# MAX32550 register map
Vendor: Maxim Integrated; File version: 1.0
Registers are 32-bit, read-write, reset 0x0 unless marked. A register's access mark holds for its fields unless they carry their own. Offsets are from the block's base; [hi:lo] are bit positions; {n}, {i} and the like mark numbered series; 'fields as' and 'values as' point back to an identical list.

## SPI0 — Serial Peripheral Interface
Base 0x40018000; register names take the prefix SPI0_
Same registers: SPI1 0x40019000 (register names take the prefix SPI1_), SPI2 0x4001A000 (register names take the prefix SPI2_)
0x00 DATA 16-bit — SPI Data
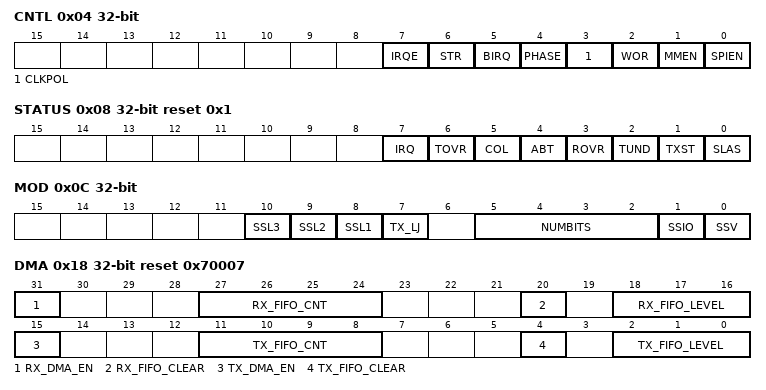
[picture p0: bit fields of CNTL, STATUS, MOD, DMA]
0x04 CNTL — SPI Control Register
  [7] IRQE — Interrupt Request Enable
    0=disable; 1=enable
  [6] STR — Start SPI Interrupt
    0=complete (No operation/complete); 1=Start operation
  [5] BIRQ — Baud Rate Generator Timer Interrupt Request
    0=disable; 1=enable
  [4] PHASE — Phase Select
    0=activeEdge (Transmit on active edge of SCLK); 1=inactiveEdge (Transmit on inactive edge of SCLK)
  [3] CLKPOL — Clock Polarity
    0=idleLo (SCLK idles Low (0) after character transmission/reception.); 1=idleHi (SCLK idles High (1) after character transmission/reception.)
  [2] WOR — Wired OR (open drain) Enable
    0=disable; 1=enable
  [1] MMEN — SPI Master Mode Enable
    0=slave; 1=master
  [0] SPIEN — SPI Enable
    0=disable; 1=enable
0x08 STATUS reset 0x1 — SPI Status Register
  [7] IRQ write-1-clears — SPI Interrupt Request
    0=inactive (No interrupt is pending.); 1=pending (An interrupt is pending.)
  [6] TOVR write-1-clears — Transmit Overrun
    0=noEvent (The event has not occurred); 1=occurred (The event has occurred.)
  [5] COL write-1-clears — Collision
    values as TOVR
  [4] ABT write-1-clears — Slave Mode Transaction Abort
    values as TOVR
  [3] ROVR write-1-clears — Receive Overrun
    values as TOVR
  [2] TUND write-1-clears — Transmit Underrun
    values as TOVR
  [1] TXST ro — Transmit Status
    0=idle; 1=busy
  [0] SLAS ro — Slave Select. If the SPI is in slave mode, this bit indicates if the SPI is selected. If the SPI is in master mode this bit has no meaning.
    0=selected; 1=notSelected
0x0C MOD — SPI Mode Register
  [10] SSL3 — Slave Select 3. If SPI is enabled and in master mode, the SSEL_3 is driven according to this bit.
    0=hi (High); 1=lo (Low)
  [9] SSL2 — Slave Select 2. If SPI is enabled and in master mode, the SSEL_2 is driven according to this bit.
    0=hi (High); 1=lo (Low)
  [8] SSL1 — Slave Select 1. If SPI is enabled and in master mode, the SSEL_1 is driven according to this bit.
    0=hi (High); 1=lo (Low)
  [7] TX_LJ — Transmit Left Justify
    0=disable; 1=enable
  [5:2] NUMBITS
    0=bits16; {v}=bits{v} (v=1..15)
  [1] SSIO — Slave Select I/O
    0=input; 1=output
  [0] SSV — Slave Select Value
    0=lo (The SSEL pin will be driven low.); 1=hi (The SSEL pin will be driven high.)
0x14 BRG 16-bit reset 0xFFFF — Baud Rate Reload Value. The SPI Baud Rate register is a 16-bit reload value for the SPI Baud Rate Generator. The reload value must be greater than or equal to 0002H for proper SPI operation (maximum baud rate is PCLK frequency divided by 4).
0x18 DMA reset 0x70007 — SPI DMA Register
  [31] RX_DMA_EN — Receive DMA Enable
    0=disable; 1=enable
  [27:24] RX_FIFO_CNT ro — Receive FIFO Count
  [20] RX_FIFO_CLEAR wo — Receive FIFO Clear
    0=complete (No operation/complete); 1=Start operation
  [18:16] RX_FIFO_LEVEL — Receive FIFO Level. Sets the RX FIFO DMA request threshold. This configures the number of filled RxFIFO entries before activating an RxDMA request.
    0=entry1; {v}=entries{v+1} (v=1..7)
  [15] TX_DMA_EN — Transmit DMA Enable
    0=disable; 1=enable
  [11:8] TX_FIFO_CNT ro — Transmit FIFO Count.
  [4] TX_FIFO_CLEAR wo — Transmit FIFO Clear
    0=complete (No operation/complete); 1=Start operation
  [2:0] TX_FIFO_LEVEL — Transmit FIFO Level. Set the number of free entries in the TxFIFO when a TxDMA request occurs.
    0=entry1; {v}=entries{v+1} (v=1..7)
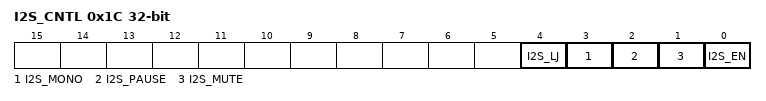
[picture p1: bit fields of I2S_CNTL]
0x1C I2S_CNTL — I2S Control Register
  [all] fields
    0=disable; 1=enable
  [4] I2S_LJ — I2S Left Justify
  [3] I2S_MONO — I2S Monophonic Audio Mode
  [2] I2S_PAUSE — I2S Pause transmit/receive
  [1] I2S_MUTE — I2S Mute transmit
  [0] I2S_EN — I2S Mode Enable
